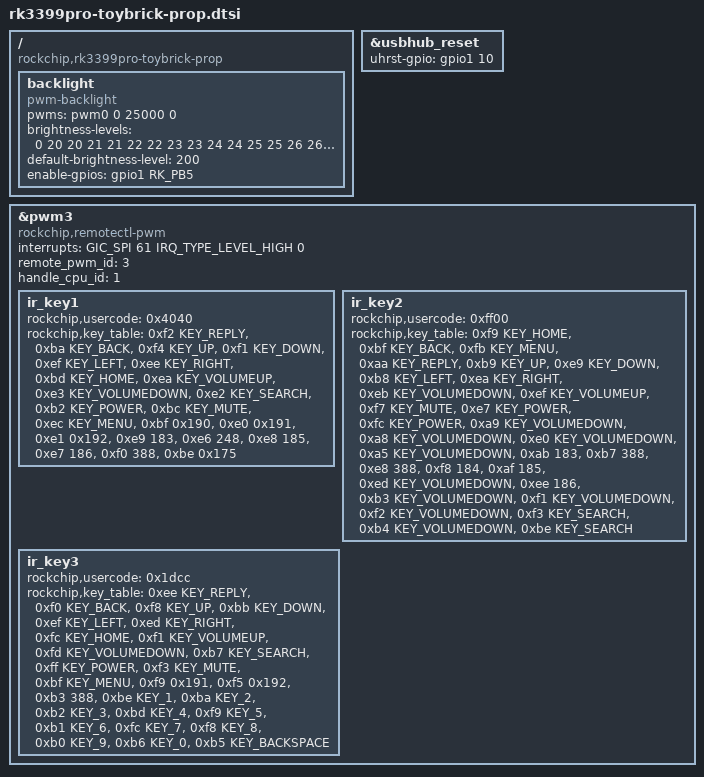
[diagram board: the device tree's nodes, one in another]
#include "rk3399pro-toybrick.dtsi"
#include "rk3399-vop-clk-set.dtsi"
#include "rk3399-android.dtsi"

/ {
	compatible = "rockchip,rk3399pro-toybrick-prop","rockchip,rk3399pro";

	backlight: backlight {
		compatible = "pwm-backlight";
		pwms = <&pwm0 0 25000 0>;
		brightness-levels = <
			  0  20  20  21  21  22  22  23
			 23  24  24  25  25  26  26  27
			 27  28  28  29  29  30  30  31
			 31  32  32  33  33  34  34  35
			 35  36  36  37  37  38  38  39
			 40  41  42  43  44  45  46  47
			 48  49  50  51  52  53  54  55
			 56  57  58  59  60  61  62  63
			 64  65  66  67  68  69  70  71
			 72  73  74  75  76  77  78  79
			 80  81  82  83  84  85  86  87
			 88  89  90  91  92  93  94  95
			 96  97  98  99 100 101 102 103
			104 105 106 107 108 109 110 111
			112 113 114 115 116 117 118 119
			120 121 122 123 124 125 126 127
			128 129 130 131 132 133 134 135
			136 137 138 139 140 141 142 143
			144 145 146 147 148 149 150 151
			152 153 154 155 156 157 158 159
			160 161 162 163 164 165 166 167
			168 169 170 171 172 173 174 175
			176 177 178 179 180 181 182 183
			184 185 186 187 188 189 190 191
			192 193 194 195 196 197 198 199
			200 201 202 203 204 205 206 207
			208 209 210 211 212 213 214 215
			216 217 218 219 220 221 222 223
			224 225 226 227 228 229 230 231
			232 233 234 235 236 237 238 239
			240 241 242 243 244 245 246 247
			248 249 250 251 252 253 254 255
		>;
		default-brightness-level = <200>;
		enable-gpios = <&gpio1 RK_PB5 GPIO_ACTIVE_HIGH>;
	};

};

&usbhub_reset {
    uhrst-gpio = <&gpio1 10 GPIO_ACTIVE_HIGH>;
};

&pwm3 {
	status = "okay";
    pinctrl-names = "default";
	interrupts = <GIC_SPI 61 IRQ_TYPE_LEVEL_HIGH 0>;
	compatible = "rockchip,remotectl-pwm";
	remote_pwm_id = <3>;
	handle_cpu_id = <1>;

	ir_key1 {
		rockchip,usercode = <0x4040>;
		rockchip,key_table =
			<0xf2	KEY_REPLY>,
			<0xba	KEY_BACK>,
			<0xf4	KEY_UP>,
			<0xf1	KEY_DOWN>,
			<0xef	KEY_LEFT>,
			<0xee	KEY_RIGHT>,
			<0xbd	KEY_HOME>,
			<0xea	KEY_VOLUMEUP>,
			<0xe3	KEY_VOLUMEDOWN>,
			<0xe2	KEY_SEARCH>,
			<0xb2	KEY_POWER>,
			<0xbc	KEY_MUTE>,
			<0xec	KEY_MENU>,
			<0xbf	0x190>,
			<0xe0	0x191>,
			<0xe1	0x192>,
			<0xe9	183>,
			<0xe6	248>,
			<0xe8	185>,
			<0xe7	186>,
			<0xf0	388>,
			<0xbe	0x175>;
	};

	ir_key2 {
		rockchip,usercode = <0xff00>;
		rockchip,key_table =
			<0xf9	KEY_HOME>,
			<0xbf	KEY_BACK>,
			<0xfb	KEY_MENU>,
			<0xaa	KEY_REPLY>,
			<0xb9	KEY_UP>,
			<0xe9	KEY_DOWN>,
			<0xb8	KEY_LEFT>,
			<0xea	KEY_RIGHT>,
			<0xeb	KEY_VOLUMEDOWN>,
			<0xef	KEY_VOLUMEUP>,
			<0xf7	KEY_MUTE>,
			<0xe7	KEY_POWER>,
			<0xfc	KEY_POWER>,
			<0xa9	KEY_VOLUMEDOWN>,
			<0xa8	KEY_VOLUMEDOWN>,
			<0xe0	KEY_VOLUMEDOWN>,
			<0xa5	KEY_VOLUMEDOWN>,
			<0xab	183>,
			<0xb7	388>,
			<0xe8	388>,
			<0xf8	184>,
			<0xaf	185>,
			<0xed	KEY_VOLUMEDOWN>,
			<0xee	186>,
			<0xb3	KEY_VOLUMEDOWN>,
			<0xf1	KEY_VOLUMEDOWN>,
			<0xf2	KEY_VOLUMEDOWN>,
			<0xf3	KEY_SEARCH>,
			<0xb4	KEY_VOLUMEDOWN>,
			<0xbe	KEY_SEARCH>;
	};

	ir_key3 {
		rockchip,usercode = <0x1dcc>;
		rockchip,key_table =
			<0xee	KEY_REPLY>,
			<0xf0	KEY_BACK>,
			<0xf8	KEY_UP>,
			<0xbb	KEY_DOWN>,
			<0xef	KEY_LEFT>,
			<0xed	KEY_RIGHT>,
			<0xfc	KEY_HOME>,
			<0xf1	KEY_VOLUMEUP>,
			<0xfd	KEY_VOLUMEDOWN>,
			<0xb7	KEY_SEARCH>,
			<0xff	KEY_POWER>,
			<0xf3	KEY_MUTE>,
			<0xbf	KEY_MENU>,
			<0xf9	0x191>,
			<0xf5	0x192>,
			<0xb3	388>,
			<0xbe	KEY_1>,
			<0xba	KEY_2>,
			<0xb2	KEY_3>,
			<0xbd	KEY_4>,
			<0xf9	KEY_5>,
			<0xb1	KEY_6>,
			<0xfc	KEY_7>,
			<0xf8	KEY_8>,
			<0xb0	KEY_9>,
			<0xb6	KEY_0>,
			<0xb5	KEY_BACKSPACE>;
	};
};

